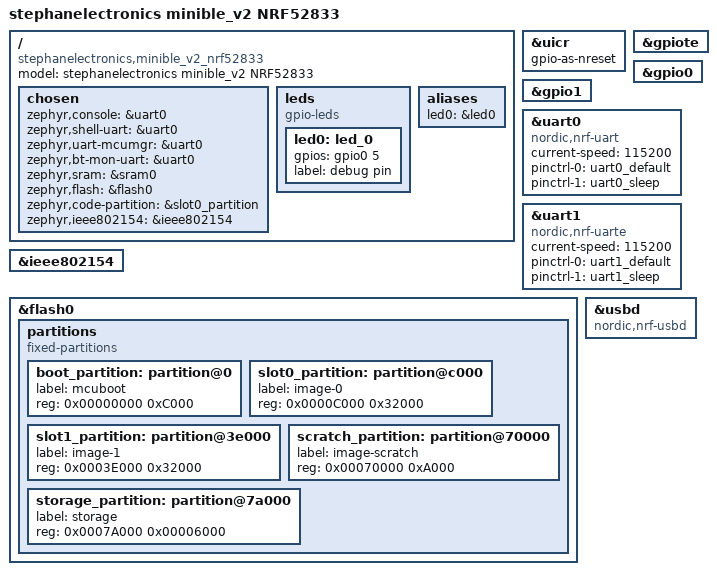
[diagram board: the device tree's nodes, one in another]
/dts-v1/;
#include <nordic/nrf52833_qiaa.dtsi>
#include "minible_v2_nrf52833-pinctrl.dtsi"

/ {
	model = "stephanelectronics minible_v2 NRF52833";
	compatible = "stephanelectronics,minible_v2_nrf52833";

	chosen {
		zephyr,console = &uart0;
		zephyr,shell-uart = &uart0;
		zephyr,uart-mcumgr = &uart0;
		zephyr,bt-mon-uart = &uart0;
		zephyr,sram = &sram0;
		zephyr,flash = &flash0;
		zephyr,code-partition = &slot0_partition;
		zephyr,ieee802154 = &ieee802154;
	};

	leds {
		compatible = "gpio-leds";
		led0: led_0 {
			gpios = <&gpio0 5 GPIO_ACTIVE_HIGH>;
			label = "debug pin";
		};
	};

	aliases {
		led0 = &led0;
	};
};

&uicr {
	gpio-as-nreset;
};

&gpiote {
	status = "okay";
};

&gpio0 {
	status = "okay";
};

&gpio1 {
	status = "okay";
};

&uart0 {
	compatible = "nordic,nrf-uart";
	status = "okay";
	current-speed = <115200>;
	pinctrl-0 = <&uart0_default>;
	pinctrl-1 = <&uart0_sleep>;
	pinctrl-names = "default", "sleep";
};

&uart1 {
	compatible = "nordic,nrf-uarte";
	status = "okay";
	current-speed = <115200>;
	pinctrl-0 = <&uart1_default>;
	pinctrl-1 = <&uart1_sleep>;
	pinctrl-names = "default", "sleep";
};

&ieee802154 {
	status = "okay";
};

&flash0 {
	partitions {
		compatible = "fixed-partitions";
		#address-cells = <1>;
		#size-cells = <1>;

		boot_partition: partition@0 {
			label = "mcuboot";
			reg = <0x00000000 0xC000>;
		};
		slot0_partition: partition@c000 {
			label = "image-0";
			reg = <0x0000C000 0x32000>;
		};
		slot1_partition: partition@3e000 {
			label = "image-1";
			reg = <0x0003E000 0x32000>;
		};
		scratch_partition: partition@70000 {
			label = "image-scratch";
			reg = <0x00070000 0xA000>;
		};
		storage_partition: partition@7a000 {
			label = "storage";
			reg = <0x0007A000 0x00006000>;
		};
	};
};

zephyr_udc0: &usbd {
	compatible = "nordic,nrf-usbd";
	status = "okay";
};
